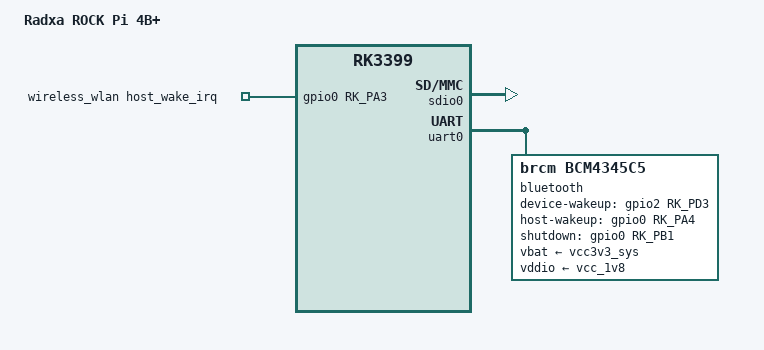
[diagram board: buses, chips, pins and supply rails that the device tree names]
// SPDX-License-Identifier: (GPL-2.0+ OR MIT)
/*
 * Copyright (c) 2019 Akash Gajjar <Akash_Gajjar@mentor.com>
 * Copyright (c) 2019 Pragnesh Patel <Pragnesh_Patel@mentor.com>
 */

/dts-v1/;
#include "rk3399-rock-pi-4.dtsi"
#include "rk3399-op1-opp.dtsi"

/ {
	model = "Radxa ROCK Pi 4B+";
	compatible = "radxa,rockpi4b-plus", "radxa,rockpi4", "rockchip,rk3399";

	wireless_wlan: wireless-wlan {
		compatible = "wlan-platdata";
		rockchip,grf = <&grf>;
		wifi_chip_type = "ap6256";
		pinctrl-names = "default";
		pinctrl-0 = <&wifi_host_wake_l>;
		WIFI,host_wake_irq = <&gpio0 RK_PA3 GPIO_ACTIVE_HIGH>;
		status = "okay";
	};
};

&pinctrl {
	usb2 {
		vcc5v0_host_en: vcc5v0-host-en {
			rockchip,pins = <4 RK_PD1 RK_FUNC_GPIO &pcfg_pull_none>;
		};
	};
};

&sdio0 {
	status = "okay";
};

&uart0 {
	status = "okay";

	bluetooth {
		compatible = "brcm,bcm4345c5";
		clocks = <&rk808 1>;
		clock-names = "lpo";
		device-wakeup-gpios = <&gpio2 RK_PD3 GPIO_ACTIVE_HIGH>;
		host-wakeup-gpios = <&gpio0 RK_PA4 GPIO_ACTIVE_HIGH>;
		shutdown-gpios = <&gpio0 RK_PB1 GPIO_ACTIVE_HIGH>;
		max-speed = <1500000>;
		pinctrl-names = "default";
		pinctrl-0 = <&bt_host_wake_l &bt_wake_l &bt_enable_h>;
		vbat-supply = <&vcc3v3_sys>;
		vddio-supply = <&vcc_1v8>;
	};
};

&vcc5v0_host {
	enable-active-high;
	gpio = <&gpio4 RK_PD1 GPIO_ACTIVE_HIGH>;
	pinctrl-names = "default";
	pinctrl-0 = <&vcc5v0_host_en>;
};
